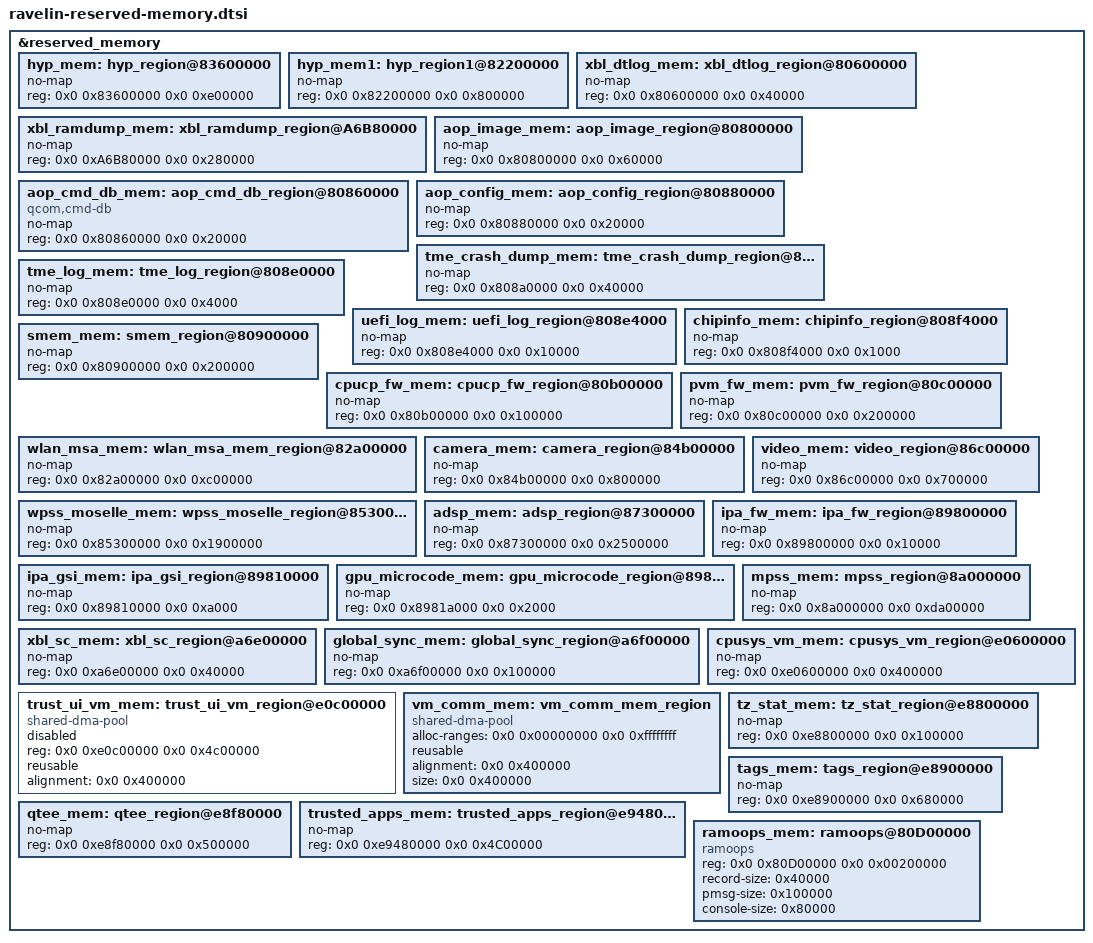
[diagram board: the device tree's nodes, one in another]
// SPDX-License-Identifier: BSD-3-Clause
/*
 * Copyright (c) Qualcomm Technologies, Inc. and/or its subsidiaries.
 */

&reserved_memory {
	#address-cells = <2>;
	#size-cells = <2>;
	ranges;

	hyp_mem: hyp_region@83600000 {
		no-map;
		reg = <0x0 0x83600000 0x0 0xe00000>;
	};

	hyp_mem1: hyp_region1@82200000 {
		no-map;
		reg = <0x0 0x82200000 0x0 0x800000>;
	};

	xbl_dtlog_mem: xbl_dtlog_region@80600000 {
		no-map;
		reg = <0x0 0x80600000 0x0 0x40000>;
	};

        xbl_ramdump_mem: xbl_ramdump_region@A6B80000 {
		no-map;
		reg = <0x0 0xA6B80000 0x0 0x280000>;
	};

	aop_image_mem: aop_image_region@80800000 {
		no-map;
		reg = <0x0 0x80800000 0x0 0x60000>;
	};

	aop_cmd_db_mem: aop_cmd_db_region@80860000 {
		compatible = "qcom,cmd-db";
		no-map;
		reg = <0x0 0x80860000 0x0 0x20000>;
	};

	aop_config_mem: aop_config_region@80880000 {
		no-map;
		reg = <0x0 0x80880000 0x0 0x20000>;
	};

	tme_crash_dump_mem: tme_crash_dump_region@808a0000 {
		no-map;
		reg = <0x0 0x808a0000 0x0 0x40000>;
	};

	tme_log_mem: tme_log_region@808e0000 {
		no-map;
		reg = <0x0 0x808e0000 0x0 0x4000>;
	};

	uefi_log_mem: uefi_log_region@808e4000 {
		no-map;
		reg = <0x0 0x808e4000 0x0 0x10000>;
	};

	chipinfo_mem: chipinfo_region@808f4000 {
		no-map;
		reg = <0x0 0x808f4000 0x0 0x1000>;
	};

	smem_mem: smem_region@80900000 {
		no-map;
		reg = <0x0 0x80900000 0x0 0x200000>;
	};

	cpucp_fw_mem: cpucp_fw_region@80b00000 {
		no-map;
		reg = <0x0 0x80b00000 0x0 0x100000>;
	};

	pvm_fw_mem: pvm_fw_region@80c00000 {
		no-map;
		reg = <0x0 0x80c00000 0x0 0x200000>;
	};

	wlan_msa_mem: wlan_msa_mem_region@82a00000 {
		no-map;
		reg = <0x0 0x82a00000 0x0 0xc00000>;
	};

	camera_mem: camera_region@84b00000 {
		no-map;
		reg = <0x0 0x84b00000 0x0 0x800000>;
	};

	wpss_moselle_mem: wpss_moselle_region@85300000 {
		no-map;
		reg = <0x0 0x85300000 0x0 0x1900000>;
	};

	video_mem: video_region@86c00000 {
		no-map;
		reg = <0x0 0x86c00000 0x0 0x700000>;
	};

	adsp_mem: adsp_region@87300000 {
		no-map;
		reg = <0x0 0x87300000 0x0 0x2500000>;
	};

	ipa_fw_mem: ipa_fw_region@89800000 {
		no-map;
		reg = <0x0 0x89800000 0x0 0x10000>;
	};

	ipa_gsi_mem: ipa_gsi_region@89810000 {
		no-map;
		reg = <0x0 0x89810000 0x0 0xa000>;
	};

	gpu_microcode_mem: gpu_microcode_region@8981a000 {
		no-map;
		reg = <0x0 0x8981a000 0x0 0x2000>;
	};

	mpss_mem: mpss_region@8a000000 {
		no-map;
		reg = <0x0 0x8a000000 0x0 0xda00000>;
	};

	xbl_sc_mem: xbl_sc_region@a6e00000 {
		no-map;
		reg = <0x0 0xa6e00000 0x0 0x40000>;
	};

	global_sync_mem: global_sync_region@a6f00000 {
		no-map;
		reg = <0x0 0xa6f00000 0x0 0x100000>;
	};

	cpusys_vm_mem: cpusys_vm_region@e0600000 {
		no-map;
		reg = <0x0 0xe0600000 0x0 0x400000>;
	};

	trust_ui_vm_mem: trust_ui_vm_region@e0c00000 {
		compatible = "shared-dma-pool";
		reg = <0x0 0xe0c00000 0x0 0x4c00000>;
		reusable;
		alignment = <0x0 0x400000>;
		status = "disabled";
	};

	vm_comm_mem: vm_comm_mem_region {
		compatible = "shared-dma-pool";
		alloc-ranges = <0x0 0x00000000 0x0 0xffffffff>;
		reusable;
		alignment = <0x0 0x400000>;
		size = <0x0 0x400000>;
	};

	tz_stat_mem: tz_stat_region@e8800000 {
		no-map;
		reg = <0x0 0xe8800000 0x0 0x100000>;
	};

	tags_mem: tags_region@e8900000 {
		no-map;
		reg = <0x0 0xe8900000 0x0 0x680000>;
	};

	qtee_mem: qtee_region@e8f80000 {
		no-map;
		reg = <0x0 0xe8f80000 0x0 0x500000>;
	};

	trusted_apps_mem: trusted_apps_region@e9480000 {
		no-map;
		reg = <0x0 0xe9480000 0x0 0x4C00000>;
	};

        ramoops_mem: ramoops@80D00000 {
		compatible = "ramoops";
		reg = <0x0 0x80D00000 0x0 0x00200000>;
		record-size = <0x40000>;
		pmsg-size = <0x100000>;
		console-size = <0x80000>;
	};

};
